VERSION ""

NS_ :

BS_:

BU_: MINS525_CAN

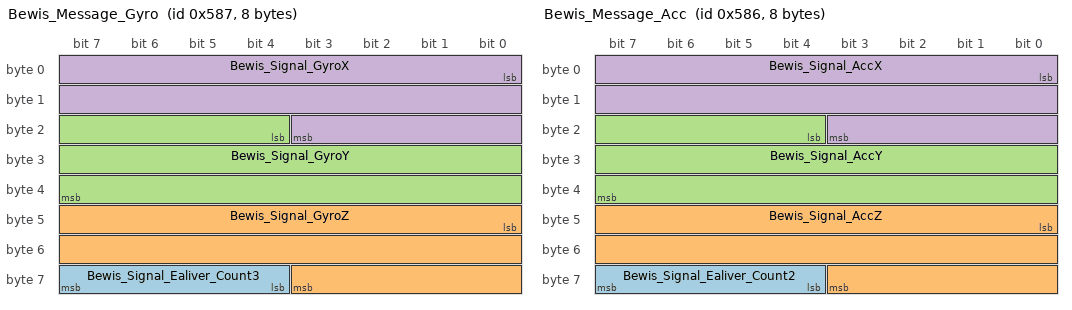
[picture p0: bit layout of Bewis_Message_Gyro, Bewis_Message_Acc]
BO_ 1415 Bewis_Message_Gyro: 8 Vector__XXX
 SG_ Bewis_Signal_Ealiver_Count3 : 60|4@1+ (1,0) [0|15] "" Vector__XXX
 SG_ Bewis_Signal_GyroZ : 40|20@1- (0.001,0) [-500|500] "бу/s" Vector__XXX
 SG_ Bewis_Signal_GyroY : 20|20@1- (0.001,0) [-500|500] "бу/s" Vector__XXX
 SG_ Bewis_Signal_GyroX : 0|20@1- (0.001,0) [-500|500] "бу/s" Vector__XXX

BO_ 1414 Bewis_Message_Acc: 8 Vector__XXX
 SG_ Bewis_Signal_Ealiver_Count2 : 60|4@1+ (1,0) [0|15] "" Vector__XXX
 SG_ Bewis_Signal_AccZ : 40|20@1- (0.0001,0) [-5|5] "g" Vector__XXX
 SG_ Bewis_Signal_AccY : 20|20@1- (0.0001,0) [-5|5] "g" Vector__XXX
 SG_ Bewis_Signal_AccX : 0|20@1- (0.0001,0) [-5|5] "g" Vector__XXX

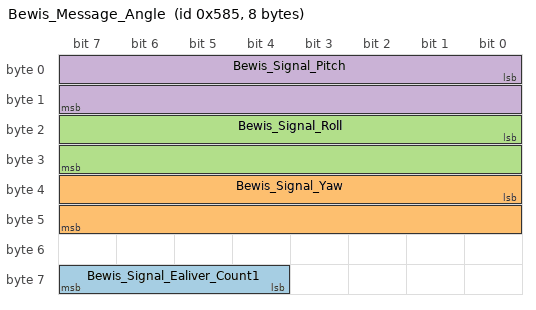
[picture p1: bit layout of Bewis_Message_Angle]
BO_ 1413 Bewis_Message_Angle: 8 MINS525_CAN
 SG_ Bewis_Signal_Ealiver_Count1 : 60|4@1+ (1,0) [0|15] "" Vector__XXX
 SG_ Bewis_Signal_Yaw : 32|16@1+ (0.01,0) [0|360] "бу" Vector__XXX
 SG_ Bewis_Signal_Roll : 16|16@1- (0.01,0) [-180|180] "бу" Vector__XXX
 SG_ Bewis_Signal_Pitch : 0|16@1- (0.01,0) [-90|90] "бу" Vector__XXX

BA_DEF_ SG_  "GenSigSendType" ENUM  "Cyclic","OnWrite","OnWriteWithRepetition","OnChange","OnChangeWithRepetition","IfActive","IfActiveWithRepetition","NoSigSendType";
BA_DEF_ BO_  "GenMsgSendType" ENUM  "Cyclic","not_used","not_used","not_used","not_used","Cyclic","not_used","IfActive","NoMsgSendType";
BA_DEF_  "DBName" STRING ;
BA_DEF_  "BusType" STRING ;
BA_DEF_DEF_  "GenSigSendType" "Cyclic";
BA_DEF_DEF_  "GenMsgSendType" "NoMsgSendType";
BA_DEF_DEF_  "DBName" "";
BA_DEF_DEF_  "BusType" "CAN";
BA_ "DBName" "MINS525CAN";
